# MCU_FSS0_HPB_ECC_AGGR register map
Vendor: Texas Instruments
Peripheral module from a debugger description file (folder am65x).
Registers are 32-bit, access not given, reset 0x0 unless marked. A register's access mark holds for its fields unless they carry their own. Offsets are as the file gives them; lines under a group give offsets from that group; [hi:lo] are bit positions; {n}, {i} and the like mark numbered series; 'fields as' and 'values as' point back to an identical list; <NAME> marks a mode.

## MCU_FSS0_HPB_ECC_AGGR
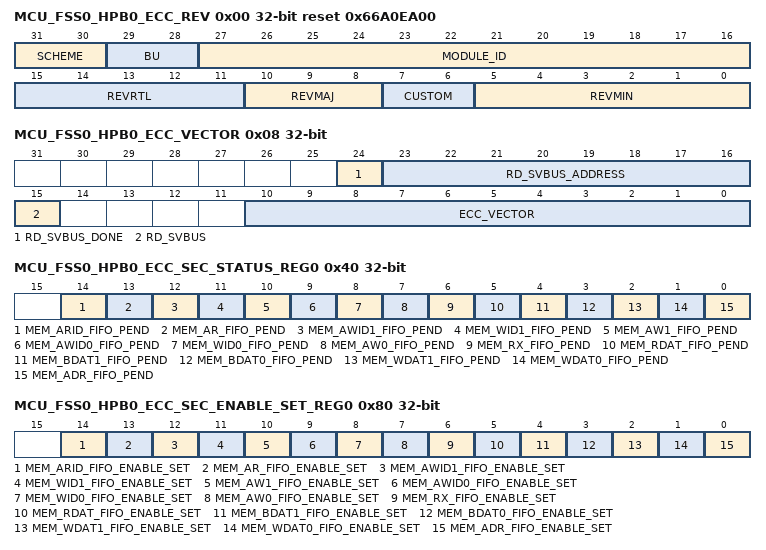
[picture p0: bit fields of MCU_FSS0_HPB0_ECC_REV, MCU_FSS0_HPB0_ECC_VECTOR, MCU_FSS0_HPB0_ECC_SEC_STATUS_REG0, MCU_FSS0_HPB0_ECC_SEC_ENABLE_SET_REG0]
0x00 MCU_FSS0_HPB0_ECC_REV ro reset 0x66A0EA00 — Aggregator Revision Register Revision parameters.
  [31:30] SCHEME
  [29:28] BU — Business Unit
  [27:16] MODULE_ID
  [15:11] REVRTL — RTL Version
  [10:8] REVMAJ — Major Version
  [7:6] CUSTOM — Custom Version
  [5:0] REVMIN — Minor Version
0x08 MCU_FSS0_HPB0_ECC_VECTOR — ECC Vector Register
  [24] RD_SVBUS_DONE — Read Done Status to indicate if read on the serial ECC interface is complete, write of any value will clear this bit. (access RW1C)
  [23:16] RD_SVBUS_ADDRESS rw — Read Address
  [15] RD_SVBUS — Read Trigger Write 1h to trigger a read on the serial ECC interface. (access RW1S)
  [10:0] ECC_VECTOR rw — ECC RAM ID Value written to select the corresponding ECC RAM for control or status.
0x0C MCU_FSS0_HPB0_ECC_STAT ro reset 0xF — Misc Status Register
  [10:0] NUM_RAMS — Number of RAMs Indicates the number of RAMs serviced by the ECC Aggregator.
0x3C MCU_FSS0_HPB0_ECC_SEC_EOI_REG — End Of Interrupt (EOI) Register The EOI register is used to re-trigger the pulse interrupt signal to ensure that any nested interrupt events are serviced. The software interrupt handler must write to the EOI register at the end of the current interrupt processing routine, so that new events can re-trigger the pulse interrupt signal again. For level interrupt signals the EOI register is not functional and must not be used.
  [0] EOI_WR — EOI (access RW1S)
0x40 MCU_FSS0_HPB0_ECC_SEC_STATUS_REG0 — SEC Interrupt Status Register 0
  [14] MEM_ARID_FIFO_PEND — Interrupt Pending Status for mem_arid_fifo_pend (access RW1S)
  [13] MEM_AR_FIFO_PEND — Interrupt Pending Status for mem_ar_fifo_pend (access RW1S)
  [12] MEM_AWID1_FIFO_PEND — Interrupt Pending Status for mem_awid1_fifo_pend (access RW1S)
  [11] MEM_WID1_FIFO_PEND — Interrupt Pending Status for mem_wid1_fifo_pend (access RW1S)
  [10] MEM_AW1_FIFO_PEND — Interrupt Pending Status for mem_aw1_fifo_pend (access RW1S)
  [9] MEM_AWID0_FIFO_PEND — Interrupt Pending Status for mem_awid0_fifo_pend (access RW1S)
  [8] MEM_WID0_FIFO_PEND — Interrupt Pending Status for mem_wid0_fifo_pend (access RW1S)
  [7] MEM_AW0_FIFO_PEND — Interrupt Pending Status for mem_aw0_fifo_pend (access RW1S)
  [6] MEM_RX_FIFO_PEND — Interrupt Pending Status for mem_rx_fifo_pend (access RW1S)
  [5] MEM_RDAT_FIFO_PEND — Interrupt Pending Status for mem_rdat_fifo_pend (access RW1S)
  [4] MEM_BDAT1_FIFO_PEND — Interrupt Pending Status for mem_bdat1_fifo_pend (access RW1S)
  [3] MEM_BDAT0_FIFO_PEND — Interrupt Pending Status for mem_bdat0_fifo_pend (access RW1S)
  [2] MEM_WDAT1_FIFO_PEND — Interrupt Pending Status for mem_wdat1_fifo_pend (access RW1S)
  [1] MEM_WDAT0_FIFO_PEND — Interrupt Pending Status for mem_wdat0_fifo_pend (access RW1S)
  [0] MEM_ADR_FIFO_PEND — Interrupt Pending Status for mem_adr_fifo_pend (access RW1S)
0x80 MCU_FSS0_HPB0_ECC_SEC_ENABLE_SET_REG0 — SEC Interrupt Enable Set Register 0
  [14] MEM_ARID_FIFO_ENABLE_SET — Interrupt Enable Set Register for mem_arid_fifo_pend (access RW1S)
  [13] MEM_AR_FIFO_ENABLE_SET — Interrupt Enable Set Register for mem_ar_fifo_pend (access RW1S)
  [12] MEM_AWID1_FIFO_ENABLE_SET — Interrupt Enable Set Register for mem_awid1_fifo_pend (access RW1S)
  [11] MEM_WID1_FIFO_ENABLE_SET — Interrupt Enable Set Register for mem_wid1_fifo_pend (access RW1S)
  [10] MEM_AW1_FIFO_ENABLE_SET — Interrupt Enable Set Register for mem_aw1_fifo_pend (access RW1S)
  [9] MEM_AWID0_FIFO_ENABLE_SET — Interrupt Enable Set Register for mem_awid0_fifo_pend (access RW1S)
  [8] MEM_WID0_FIFO_ENABLE_SET — Interrupt Enable Set Register for mem_wid0_fifo_pend (access RW1S)
  [7] MEM_AW0_FIFO_ENABLE_SET — Interrupt Enable Set Register for mem_aw0_fifo_pend (access RW1S)
  [6] MEM_RX_FIFO_ENABLE_SET — Interrupt Enable Set Register for mem_rx_fifo_pend (access RW1S)
  [5] MEM_RDAT_FIFO_ENABLE_SET — Interrupt Enable Set Register for mem_rdat_fifo_pend (access RW1S)
  [4] MEM_BDAT1_FIFO_ENABLE_SET — Interrupt Enable Set Register for mem_bdat1_fifo_pend (access RW1S)
  [3] MEM_BDAT0_FIFO_ENABLE_SET — Interrupt Enable Set Register for mem_bdat0_fifo_pend (access RW1S)
  [2] MEM_WDAT1_FIFO_ENABLE_SET — Interrupt Enable Set Register for mem_wdat1_fifo_pend (access RW1S)
  [1] MEM_WDAT0_FIFO_ENABLE_SET — Interrupt Enable Set Register for mem_wdat0_fifo_pend (access RW1S)
  [0] MEM_ADR_FIFO_ENABLE_SET — Interrupt Enable Set Register for mem_adr_fifo_pend (access RW1S)
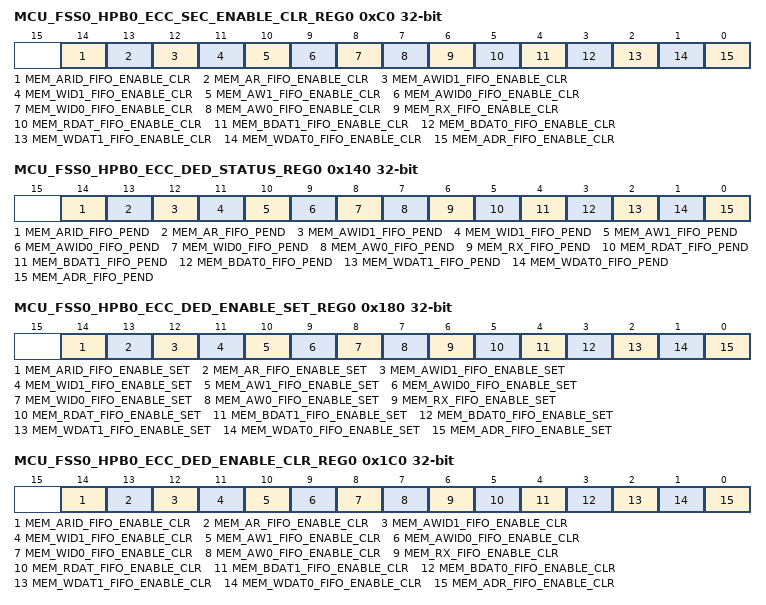
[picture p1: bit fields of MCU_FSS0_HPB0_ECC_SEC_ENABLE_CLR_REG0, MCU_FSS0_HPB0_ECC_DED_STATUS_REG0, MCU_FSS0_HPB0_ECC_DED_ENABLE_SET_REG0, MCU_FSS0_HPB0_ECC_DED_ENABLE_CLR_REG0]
0xC0 MCU_FSS0_HPB0_ECC_SEC_ENABLE_CLR_REG0 — SEC Interrupt Enable Clear Register 0
  [14] MEM_ARID_FIFO_ENABLE_CLR — Interrupt Enable Clear Register for mem_arid_fifo_pend (access RW1C)
  [13] MEM_AR_FIFO_ENABLE_CLR — Interrupt Enable Clear Register for mem_ar_fifo_pend (access RW1C)
  [12] MEM_AWID1_FIFO_ENABLE_CLR — Interrupt Enable Clear Register for mem_awid1_fifo_pend (access RW1C)
  [11] MEM_WID1_FIFO_ENABLE_CLR — Interrupt Enable Clear Register for mem_wid1_fifo_pend (access RW1C)
  [10] MEM_AW1_FIFO_ENABLE_CLR — Interrupt Enable Clear Register for mem_aw1_fifo_pend (access RW1C)
  [9] MEM_AWID0_FIFO_ENABLE_CLR — Interrupt Enable Clear Register for mem_awid0_fifo_pend (access RW1C)
  [8] MEM_WID0_FIFO_ENABLE_CLR — Interrupt Enable Clear Register for mem_wid0_fifo_pend (access RW1C)
  [7] MEM_AW0_FIFO_ENABLE_CLR — Interrupt Enable Clear Register for mem_aw0_fifo_pend (access RW1C)
  [6] MEM_RX_FIFO_ENABLE_CLR — Interrupt Enable Clear Register for mem_rx_fifo_pend (access RW1C)
  [5] MEM_RDAT_FIFO_ENABLE_CLR — Interrupt Enable Clear Register for mem_rdat_fifo_pend (access RW1C)
  [4] MEM_BDAT1_FIFO_ENABLE_CLR — Interrupt Enable Clear Register for mem_bdat1_fifo_pend (access RW1C)
  [3] MEM_BDAT0_FIFO_ENABLE_CLR — Interrupt Enable Clear Register for mem_bdat0_fifo_pend (access RW1C)
  [2] MEM_WDAT1_FIFO_ENABLE_CLR — Interrupt Enable Clear Register for mem_wdat1_fifo_pend (access RW1C)
  [1] MEM_WDAT0_FIFO_ENABLE_CLR — Interrupt Enable Clear Register for mem_wdat0_fifo_pend (access RW1C)
  [0] MEM_ADR_FIFO_ENABLE_CLR — Interrupt Enable Clear Register for mem_adr_fifo_pend (access RW1C)
0x13C MCU_FSS0_HPB0_ECC_DED_EOI_REG — DED EOI Register The EOI register is used to re-trigger the pulse interrupt signal to ensure that any nested interrupt events are serviced. The software interrupt handler must write to the EOI register at the end of the current interrupt processing routine, so that new events can re-trigger the pulse interrupt signal again. For level interrupt signals the EOI register is not functional and must not be used.
  [0] EOI_WR — EOI (access RW1S)
0x140 MCU_FSS0_HPB0_ECC_DED_STATUS_REG0 — DED Interrupt Status Register 0
  fields as MCU_FSS0_HPB0_ECC_SEC_STATUS_REG0
0x180 MCU_FSS0_HPB0_ECC_DED_ENABLE_SET_REG0 — DED Interrupt Enable Set Register 0
  fields as MCU_FSS0_HPB0_ECC_SEC_ENABLE_SET_REG0
0x1C0 MCU_FSS0_HPB0_ECC_DED_ENABLE_CLR_REG0 — DED Interrupt Enable Clear Register 0
  fields as MCU_FSS0_HPB0_ECC_SEC_ENABLE_CLR_REG0
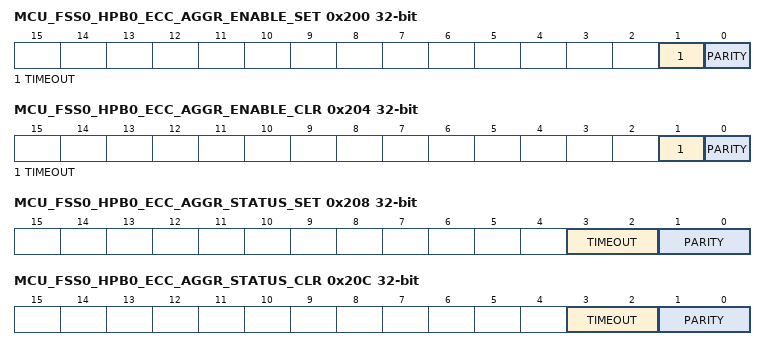
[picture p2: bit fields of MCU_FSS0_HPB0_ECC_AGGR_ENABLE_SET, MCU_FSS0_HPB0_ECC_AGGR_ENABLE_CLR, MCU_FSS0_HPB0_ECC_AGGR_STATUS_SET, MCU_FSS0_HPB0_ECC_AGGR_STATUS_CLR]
0x200 MCU_FSS0_HPB0_ECC_AGGR_ENABLE_SET — Aggregator Interrupt Enable Set Register
  [1] TIMEOUT — Interrupt enable set for ECC interface timeout errors (access RW1S)
  [0] PARITY — Interrupt enable set for parity errors (access RW1S)
0x204 MCU_FSS0_HPB0_ECC_AGGR_ENABLE_CLR — Aggregator Interrupt Enable Clear Register
  [1] TIMEOUT — Interrupt enable clear for ECC interface timeout errors (access RW1C)
  [0] PARITY — Interrupt enable clear for parity errors (access RW1C)
0x208 MCU_FSS0_HPB0_ECC_AGGR_STATUS_SET — Aggregator Interrupt Status Set Register
  [3:2] TIMEOUT — Interrupt status set for ECC interface timeout errors (access RWincr)
  [1:0] PARITY — Interrupt status set for parity errors (access RWincr)
0x20C MCU_FSS0_HPB0_ECC_AGGR_STATUS_CLR — Aggregator Interrupt Status Clear Register
  [3:2] TIMEOUT — Interrupt status clear for ECC interface timeout errors (access RWdecr)
  [1:0] PARITY — Interrupt status clear for parity errors (access RWdecr)
